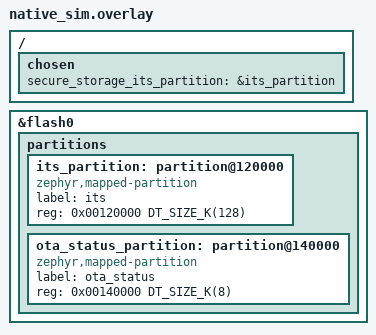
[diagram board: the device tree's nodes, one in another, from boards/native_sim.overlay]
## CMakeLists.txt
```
# Copyright 2026 NXP
#
# SPDX-License-Identifier: Apache-2.0
#

cmake_minimum_required(VERSION 3.20.0)
find_package(Zephyr REQUIRED HINTS $ENV{ZEPHYR_BASE})
project(native_sim_unit)

add_compile_definitions(ENABLE_TRACE)

target_sources(app PRIVATE
    ${ZEPHYR_NXP_IOT_AGENT_MODULE_DIR}/tests/unit/framework/test_framework.c
    ${ZEPHYR_NXP_IOT_AGENT_MODULE_DIR}/tests/unit/framework/test_utils.c
    ${ZEPHYR_NXP_IOT_AGENT_MODULE_DIR}/tests/common/canned_protobuf.c
    ${ZEPHYR_NXP_IOT_AGENT_MODULE_DIR}/tests/unit/public_ota_lib/test_el2go_ota_lib_public.c
    ${ZEPHYR_NXP_IOT_AGENT_MODULE_DIR}/tests/unit/internal_ota_lib/test_el2go_ota_lib_internal.c
    ${ZEPHYR_NXP_IOT_AGENT_MODULE_DIR}/tests/unit/internal_ota_lib/test_el2go_ota_grpc_internal.c
    ${ZEPHYR_NXP_IOT_AGENT_MODULE_DIR}/tests/unit/internal_ota_lib/test_el2go_ota_fixtures.c
    ${ZEPHYR_NXP_IOT_AGENT_MODULE_DIR}/tests/unit/internal_ota_lib/test_el2go_ota_request_builder.c
    ${ZEPHYR_NXP_IOT_AGENT_MODULE_DIR}/tests/unit/internal_ota_lib/test_el2go_ota_response_handler.c
    ${ZEPHYR_NXP_IOT_AGENT_MODULE_DIR}/tests/unit/internal_ota_lib/test_el2go_ota_status_reporting.c
    ${ZEPHYR_NXP_IOT_AGENT_MODULE_DIR}/tests/unit/internal_ota_lib/test_el2go_ota_download_engine.c
    ${ZEPHYR_NXP_IOT_AGENT_MODULE_DIR}/tests/unit/internal_ota_lib/test_el2go_ota_kvs.c
    ${ZEPHYR_NXP_IOT_AGENT_MODULE_DIR}/tests/unit/internal_ota_lib/test_el2go_ota_tls.c
    ${ZEPHYR_NXP_IOT_AGENT_MODULE_DIR}/tests/unit/internal_ota_lib/test_el2go_ota_cred_psa.c
    ${ZEPHYR_NXP_IOT_AGENT_MODULE_DIR}/tests/unit/internal_ota_lib/test_el2go_ota_lib_core.c
    ${CMAKE_CURRENT_SOURCE_DIR}/src/ztest_unit_main.c
    ${ZEPHYR_NXP_IOT_AGENT_MODULE_DIR}/zephyr/tests/common/ztest_bridge.c
    ${CMAKE_CURRENT_SOURCE_DIR}/mock/platform_stubs.c
    ${CMAKE_CURRENT_SOURCE_DIR}/mock/wrap_net_crypto.c
)

set_source_files_properties(
    ${ZEPHYR_NXP_IOT_AGENT_MODULE_DIR}/tests/unit/internal_ota_lib/test_el2go_ota_lib_internal.c
    PROPERTIES COMPILE_DEFINITIONS "register_ota_lib_tests=register_ota_lib_internal_tests"
)

# wrap flags so el2go_ota_tls.c, el2go_ota_cred_psa.c, and el2go_ota_grpc.c
# execute their real code paths while net_crypto_*/psa_its_* are stubbed.
zephyr_ld_options(
    -Wl,--wrap=net_crypto_new
    -Wl,--wrap=net_crypto_configure
    -Wl,--wrap=net_crypto_set_server_cert
    -Wl,--wrap=net_crypto_set_cli_cert
    -Wl,--wrap=net_crypto_set_cipher_suites
    -Wl,--wrap=net_crypto_set_curves
    -Wl,--wrap=net_crypto_set_alpn
    -Wl,--wrap=net_crypto_associate_key
    -Wl,--wrap=net_crypto_connect
    -Wl,--wrap=net_crypto_disconnect
    -Wl,--wrap=net_crypto_write
    -Wl,--wrap=net_crypto_read
    -Wl,--wrap=net_crypto_free
    -Wl,--wrap=secure_storage_its_get_info
    -Wl,--wrap=secure_storage_its_get
    -Wl,--wrap=psa_get_key_attributes
    -Wl,--wrap=psa_export_key
)

zephyr_compile_definitions(EL2GO_OTA_GRPC_HAVE_NET_WRAP)

zephyr_include_directories(
    ${ZEPHYR_NXP_IOT_AGENT_MODULE_DIR}/zephyr/tests/common
    ${CMAKE_CURRENT_SOURCE_DIR}/mock
    ${ZEPHYR_NXP_IOT_AGENT_MODULE_DIR}/tests/unit/mock
    ${ZEPHYR_NXP_IOT_AGENT_MODULE_DIR}/tests/common
    ${ZEPHYR_NXP_IOT_AGENT_MODULE_DIR}/tests/unit/framework
    ${ZEPHYR_NXP_IOT_AGENT_MODULE_DIR}/tests/unit/internal_ota_lib
    ${ZEPHYR_NXP_IOT_AGENT_MODULE_DIR}/tests/unit
    ${ZEPHYR_NXP_IOT_AGENT_MODULE_DIR}/include
    ${ZEPHYR_NXP_IOT_AGENT_MODULE_DIR}/priv
    ${ZEPHYR_NXP_IOT_AGENT_MODULE_DIR}/libs/protobuf/nanopb
    ${ZEPHYR_NXP_IOT_AGENT_MODULE_DIR}/libs/el2go_ota_lib/src
    ${ZEPHYR_NXP_IOT_AGENT_MODULE_DIR}/libs/el2go_ota_lib/src/cred
    ${ZEPHYR_NXP_IOT_AGENT_MODULE_DIR}/libs/el2go_ota_lib/src/osal
    ${ZEPHYR_NXP_IOT_AGENT_MODULE_DIR}/libs/el2go_ota_lib/src/download
    ${ZEPHYR_NXP_IOT_AGENT_MODULE_DIR}/libs/el2go_ota_lib/src/transport
    ${ZEPHYR_NXP_IOT_AGENT_MODULE_DIR}/libs/protobuf/ota
)

# psa-crypto public headers for the mock.
zephyr_include_directories(
    ${ZEPHYR_BASE}/../modules/crypto/tf-psa-crypto/include
    ${ZEPHYR_BASE}/../modules/crypto/tf-psa-crypto/drivers/builtin/include
    ${ZEPHYR_BASE}/../modules/crypto/mbedtls/include
    ${ZEPHYR_BASE}/subsys/secure_storage/include
    ${ZEPHYR_NXP_IOT_AGENT_MODULE_DIR}/libs/net_crypto
    ${ZEPHYR_NXP_IOT_AGENT_MODULE_DIR}/libs/platforms
)

# secure_storage_its_caller_id_t type declaration for wrap_net_crypto mocks
zephyr_include_directories(
    ${ZEPHYR_BASE}/subsys/secure_storage/include/internal
)
```

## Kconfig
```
# Copyright 2026 NXP
# SPDX-License-Identifier: Apache-2.0

config EL2GO_OTA_FWUAL_LIBRARY_SOURCES
    bool "Include FWUAL sources"

config EL2GO_OTA_LIBRARY_SOURCES
    bool "Include EL2GO OTA Library sources"

config EL2GO_OTA_TESTS
    bool "Include EL2GO OTA unit test sources"

config EL2GO_OTA_PLATFORM_SOURCES
    bool "Include EL2GO OTA platform sources"
    depends on !EL2GO_OTA_TESTS

source "Kconfig.zephyr"
```

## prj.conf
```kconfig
# Copyright 2026 NXP
# SPDX-License-Identifier: Apache-2.0

CONFIG_EL2GO_OTA_FWUAL_LIBRARY_SOURCES=y
CONFIG_EL2GO_OTA_LIBRARY_SOURCES=y
# CONFIG_EL2GO_OTA_PLATFORM_SOURCES is intentionally not set; see Kconfig.
CONFIG_EL2GO_OTA_TESTS=y

CONFIG_PRINTK=y
CONFIG_ZTEST=y

CONFIG_COMPILER_WARNINGS_AS_ERRORS=n

# PSA Crypto - mbedTLS software (no hard ELS PKC driver on native_sim)
CONFIG_PSA_CRYPTO=y
CONFIG_MBEDTLS=y
CONFIG_MBEDTLS_BUILTIN=y
CONFIG_MBEDTLS_PSA_CRYPTO_C=y
CONFIG_MBEDTLS_ENABLE_HEAP=y
CONFIG_MBEDTLS_HEAP_SIZE=65536
CONFIG_MBEDTLS_SSL_PROTO_TLS1_2=y
CONFIG_MBEDTLS_SSL_IN_CONTENT_LEN=16384
CONFIG_MBEDTLS_SSL_OUT_CONTENT_LEN=16384
CONFIG_MBEDTLS_SSL_ALPN=y
CONFIG_MBEDTLS_X509_CRT_WRITE_C=y
CONFIG_MBEDTLS_X509_CSR_WRITE_C=y
CONFIG_MBEDTLS_PK_WRITE_C=y
CONFIG_MBEDTLS_X509_CRT_PARSE_C=y
CONFIG_MBEDTLS_ASN1_PARSE_C=y
CONFIG_MBEDTLS_SSL_SERVER_NAME_INDICATION=y
CONFIG_MBEDTLS_KEY_EXCHANGE_ECDHE_ECDSA_ENABLED=y

CONFIG_PSA_CRYPTO_ENABLE_ALL=y
CONFIG_PSA_WANT_ALG_ECDSA=y
CONFIG_PSA_WANT_ALG_ECDH=y
CONFIG_PSA_WANT_ALG_SHA_256=y
CONFIG_PSA_WANT_ALG_SHA_384=y
CONFIG_PSA_WANT_ALG_GCM=y
CONFIG_PSA_WANT_ECC_SECP_R1_256=y
CONFIG_PSA_WANT_KEY_TYPE_AES=y

# Networking stack (for net_crypto/mbedTLS)
CONFIG_NETWORKING=y
CONFIG_NET_IPV4=y
CONFIG_NET_TCP=y
CONFIG_NET_SOCKETS=y

# General
CONFIG_REQUIRES_FULL_LIBC=y
CONFIG_POSIX_API=y
CONFIG_HEAP_MEM_POOL_SIZE=131072
CONFIG_MAIN_STACK_SIZE=16384
CONFIG_ZTEST_STACK_SIZE=16384
CONFIG_HWINFO=y
```

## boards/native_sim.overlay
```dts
/*
 * Copyright 2026 NXP
 *
 * SPDX-License-Identifier: Apache-2.0
 */

/ {
    chosen {
        secure_storage_its_partition = &its_partition;
    };
};

&flash0 {
    partitions {
        its_partition: partition@120000 {
            compatible = "zephyr,mapped-partition";
            label = "its";
            reg = <0x00120000 DT_SIZE_K(128)>;
        };

        ota_status_partition: partition@140000 {
            compatible = "zephyr,mapped-partition";
            label = "ota_status";
            reg = <0x00140000 DT_SIZE_K(8)>;
        };
    };
};
```

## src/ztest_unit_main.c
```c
/*
 * Copyright 2026 NXP
 *
 * SPDX-License-Identifier: Apache-2.0
 *
 */

#include <zephyr/ztest.h>

#include "test_suites.h"
#include "ztest_bridge.h"
#include "wrap_net_crypto.h"
#include "test_el2go_ota_lib_internal_suites.h"

void register_ota_lib_internal_tests(void);

/* Reset wrap_net_crypto.c mock state before every ZTEST so mock 
 * state cannot leak into another test. */
static void el2go_ota_unit_before(void *fixture)
{
    ARG_UNUSED(fixture);
    wrap_net_crypto_reset_all();
}

ZTEST_SUITE(el2go_ota_unit, NULL, NULL, el2go_ota_unit_before, NULL, NULL);

ZTEST(el2go_ota_unit, test_ota_lib_public)
{
    zassert_ok(el2go_run_suite(register_ota_lib_tests),
               "OTA lib public unit suite reported failures");
}

ZTEST(el2go_ota_unit, test_ota_lib_internal)
{
    zassert_ok(el2go_run_suite(register_ota_lib_internal_tests),
               "OTA lib internal unit suite reported failures");
}

ZTEST(el2go_ota_unit, test_ota_lib_grpc)
{
    zassert_ok(el2go_run_suite(register_ota_lib_grpc_tests),
               "OTA lib gRPC transport unit suite reported failures");
}

ZTEST(el2go_ota_unit, test_ota_lib_request_builder)
{
    zassert_ok(el2go_run_suite(register_ota_lib_request_builder_tests),
               "OTA lib request_builder unit suite reported failures");
}

ZTEST(el2go_ota_unit, test_ota_lib_response_handler)
{
    zassert_ok(el2go_run_suite(register_ota_lib_response_handler_tests),
               "OTA lib response_handler unit suite reported failures");
}

ZTEST(el2go_ota_unit, test_ota_lib_status_reporting)
{
    zassert_ok(el2go_run_suite(register_ota_lib_status_reporting_tests),
               "OTA lib status_reporting unit suite reported failures");
}

ZTEST(el2go_ota_unit, test_ota_lib_download_engine)
{
    zassert_ok(el2go_run_suite(register_ota_lib_download_engine_tests),
               "OTA lib download_engine unit suite reported failures");
}

ZTEST(el2go_ota_unit, test_ota_lib_kvs)
{
    zassert_ok(el2go_run_suite(register_ota_lib_kvs_tests),
               "OTA lib kvs unit suite reported failures");
}

ZTEST(el2go_ota_unit, test_ota_lib_tls)
{
    zassert_ok(el2go_run_suite(register_ota_lib_tls_tests),
               "OTA lib tls unit suite reported failures");
}

ZTEST(el2go_ota_unit, test_ota_lib_cred_psa)
{
    zassert_ok(el2go_run_suite(register_ota_lib_cred_psa_tests),
               "OTA lib cred_psa unit suite reported failures");
}

ZTEST(el2go_ota_unit, test_ota_lib_core)
{
    zassert_ok(el2go_run_suite(register_ota_lib_core_tests),
               "OTA lib core (el2go_ota_lib.c) unit suite reported failures");
}
```
